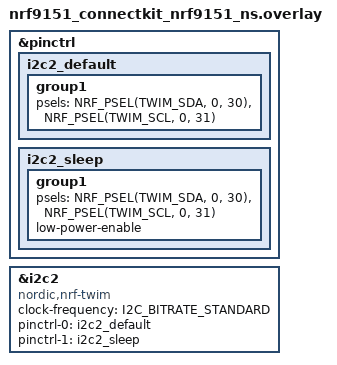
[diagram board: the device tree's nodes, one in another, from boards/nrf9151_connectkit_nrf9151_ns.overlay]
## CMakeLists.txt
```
cmake_minimum_required(VERSION 3.20.0)

find_package(Zephyr REQUIRED HINTS $ENV{ZEPHYR_BASE})
project(opencollar)

target_sources(app PRIVATE
  src/main.c
  src/app.c
  src/acks.c
  src/buzzer.c
  src/command.c
  src/config.c
  src/console.c
  src/cue.c
  src/geofence.c
  src/protocol.c
  src/provision.c
  src/rearm.c
  src/report.c
  src/shape.c
  src/slots.c
  src/store_nvs.c
  src/welfare_store.c
  third_party/monocypher/monocypher.c
  third_party/monocypher/monocypher-ed25519.c
)

target_include_directories(app PRIVATE third_party/monocypher)

# The shape rules are single precision in a fixed order of operations, to
# give the same answers as openpasture's op_geo::shape: no fused multiply-add.
target_compile_options(app PRIVATE -ffp-contract=off)
```

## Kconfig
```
mainmenu "OpenCollar"

config OPENCOLLAR_BENCH_BOUNDARY
	bool "Bench boundary from src/boundary_local.h"
	help
	  Load the boundary in src/boundary_local.h (gitignored) as version 0,
	  in RAM only, when no boundary is in force. For trying the fence and
	  cues on the bench without a server. Off on real collars, which never
	  invent a fence.

rsource "rook/Kconfig"

source "Kconfig.zephyr"
```

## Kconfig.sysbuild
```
# Partitions come from devicetree (boards/partitions_mcuboot.dtsi), not the
# Partition Manager.
config PARTITION_MANAGER
	default n

source "share/sysbuild/Kconfig"
```

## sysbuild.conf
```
# MCUboot as the first-stage bootloader; build/merged.hex = MCUboot + TF-M + app.
SB_CONFIG_BOOTLOADER_MCUBOOT=y
# DEV KEY ONLY: with no SB_CONFIG_BOOT_SIGNATURE_KEY_FILE set, images are signed
# with MCUboot's public default key (bootloader/mcuboot/root-ec-p256.pem in the
# SDK). Anyone can sign images for it. Replace with a project key kept outside
# this repo before any field build (the key is frozen into MCUboot at manufacture).
SB_CONFIG_BOOT_SIGNATURE_TYPE_ECDSA_P256=y
```

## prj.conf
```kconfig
# TF-M
CONFIG_TFM_PROFILE_TYPE_MINIMAL=y

# General
CONFIG_FPU=y
# Ed25519 checks run on the main thread, never on the system workqueue
CONFIG_MAIN_STACK_SIZE=8192
CONFIG_HEAP_MEM_POOL_SIZE=2048
CONFIG_SYSTEM_WORKQUEUE_STACK_SIZE=1536
CONFIG_POLL=y

# Logging over the USB serial port. Deferred, so printing a log line never
# holds interrupts off while a long command arrives on the same port.
CONFIG_LOG=y
CONFIG_LOG_MODE_DEFERRED=y
CONFIG_LOG_BUFFER_SIZE=4096
CONFIG_LOG_PROCESS_THREAD_STACK_SIZE=2048
CONFIG_CBPRINTF_FP_SUPPORT=y

# Console line input: provision, status and bench commands (src/console.c)
CONFIG_SERIAL=y
CONFIG_UART_INTERRUPT_DRIVEN=y

# Flash storage (NVS on the 64 KB `storage` partition): provisioning,
# config, slots and pending acks
CONFIG_FLASH=y
CONFIG_FLASH_MAP=y
CONFIG_FLASH_PAGE_LAYOUT=y
CONFIG_NVS=y
CONFIG_NVS_LOOKUP_CACHE=y
CONFIG_NVS_DATA_CRC=y
# The storage area was part of the application area before 0.2
CONFIG_NVS_INIT_BAD_MEMORY_REGION=y

# Modem and GNSS
CONFIG_NRF_MODEM_LIB=y
CONFIG_LTE_LINK_CONTROL=y

# GNSS LNA on this board is powered from the nRF9151 COEX0 pin
CONFIG_MODEM_ANTENNA=y
CONFIG_MODEM_ANTENNA_GNSS_EXTERNAL=y
CONFIG_MODEM_ANTENNA_AT_COEX0="AT%XCOEX0=1,1,1565,1586"

# Qwiic Buzzer
CONFIG_I2C=y
```

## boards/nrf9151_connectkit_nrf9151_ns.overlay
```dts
/*
 * Qwiic Buzzer on I2C2: SDA = P0.30, SCL = P0.31 (header pins 30 and 31).
 * The buzzer board has its own 2.2k pull-ups. VIO must be 3.3V (IFMCU `viosel`).
 */

/* MCUboot layout shared with the bootloader image (sysbuild/mcuboot.overlay). */
#include "partitions_mcuboot.dtsi"
#include <samples/cellular/nrf91_sram_partitions.dtsi>

&pinctrl {
	i2c2_default: i2c2_default {
		group1 {
			psels = <NRF_PSEL(TWIM_SDA, 0, 30)>,
				<NRF_PSEL(TWIM_SCL, 0, 31)>;
		};
	};

	i2c2_sleep: i2c2_sleep {
		group1 {
			psels = <NRF_PSEL(TWIM_SDA, 0, 30)>,
				<NRF_PSEL(TWIM_SCL, 0, 31)>;
			low-power-enable;
		};
	};
};

&i2c2 {
	compatible = "nordic,nrf-twim";
	status = "okay";
	clock-frequency = <I2C_BITRATE_STANDARD>;
	pinctrl-0 = <&i2c2_default>;
	pinctrl-1 = <&i2c2_sleep>;
	pinctrl-names = "default", "sleep";
};
```

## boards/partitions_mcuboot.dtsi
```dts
/*
 * Flash layout with MCUboot (NCS 3.4.1 nrf91_bootloader_partitions.dtsi
 * layout), every edge on a 32 KB SPU region boundary:
 *   0x00000-0x10000  MCUboot (64 KB)
 *   0x10000-0x80000  slot0 / primary (448 KB): TF-M 32 KB + app 416 KB
 *   0x80000-0xF0000  slot1 / secondary (448 KB), for future FOTA
 *   0xF0000-0x100000 storage (64 KB, NVS; same place as firmware 0.2)
 * Included by the app board overlay AND sysbuild/mcuboot.overlay so the
 * bootloader and the application agree on the map.
 */
#include <samples/cellular/nrf91_bootloader_partitions.dtsi>
```

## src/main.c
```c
/*
 * OpenCollar 0.2: GNSS fix -> slots and geofence -> audio cue, logged over
 * serial, with provisioning and bench commands on the same serial port.
 *
 * Boot: provisioning, config and slots come from flash (NVS); the latest
 * active boundary is enforced at once, staged ones wait for the first GNSS
 * fix. No boundary means no fence and no cues. GNSS time is the only clock
 * for boundary activation. Everything else is in app.c, which host tests
 * drive the same way. Boundary download over LTE waits for the SIM; until
 * then a signed command can be pasted on the console (`boundary <command>`).
 */
#include <zephyr/kernel.h>
#include <zephyr/logging/log.h>
#include <zephyr/sys/printk.h>
#include <modem/lte_lc.h>
#include <modem/nrf_modem_lib.h>
#include <nrf_modem_gnss.h>

#include "app.h"
#include "boundary.h"
#include "buzzer.h"
#include "console.h"
#include "store.h"

LOG_MODULE_REGISTER(opencollar, LOG_LEVEL_INF);

static const struct geofence_config geofence_defaults = {
	.warn_m = 5.0,
	.hysteresis_m = 1.0,
	.max_accuracy_m = 10.0,
};

static const struct cue_config cue_cfg = {
	.warn_freq_hz = 2730, /* Buzzer's resonant frequency: loudest */
	.outside_freq_hz = 1000,
	.beep_ms = 300,
	.max_active_ms = 20000,
	.rest_ms = 30000,
	.outside_max_ms = 10000,
	/* Welfare: PR #2 approved caps (cue.h WELFARE_DEFAULT_*). */
	.max_outside_cues = WELFARE_DEFAULT_MAX_OUTSIDE_CUES,
	.escape_cycle_limit = WELFARE_DEFAULT_ESCAPE_CYCLE_LIMIT,
	.escape_cycle_window_ms = WELFARE_DEFAULT_ESCAPE_WINDOW_MS,
};

struct fix {
	bool valid;
	bool has_time;
	double lat;
	double lon;
	float accuracy;
	uint8_t sats_tracked;
	uint8_t sats_in_fix;
	int64_t utc;
};

K_MSGQ_DEFINE(fix_q, sizeof(struct fix), 4, 8);
static struct k_poll_signal console_sig = K_POLL_SIGNAL_INITIALIZER(console_sig);

/* Everything the collar knows, in static RAM (see BUILD-LOG for the budget) */
static struct app app;
static char reply[256];
static uint32_t store_errors_seen;

static void gnss_event_handler(int event)
{
	struct nrf_modem_gnss_pvt_data_frame pvt;
	struct fix f = {0};

	if (event != NRF_MODEM_GNSS_EVT_PVT) {
		return;
	}
	if (nrf_modem_gnss_read(&pvt, sizeof(pvt), NRF_MODEM_GNSS_DATA_PVT) != 0) {
		return;
	}

	for (int i = 0; i < NRF_MODEM_GNSS_MAX_SATELLITES; i++) {
		if (pvt.sv[i].sv == 0) {
			continue;
		}
		f.sats_tracked++;
		if (pvt.sv[i].flags & NRF_MODEM_GNSS_SV_FLAG_USED_IN_FIX) {
			f.sats_in_fix++;
		}
	}

	f.valid = pvt.flags & NRF_MODEM_GNSS_PVT_FLAG_FIX_VALID;
	f.lat = pvt.latitude;
	f.lon = pvt.longitude;
	f.accuracy = pvt.accuracy;
	if (f.valid) {
		/* The fix's own UTC: the clock for boundary activation */
		f.has_time = true;
		f.utc = proto_time_civil(pvt.datetime.year, pvt.datetime.month, pvt.datetime.day,
					 pvt.datetime.hour, pvt.datetime.minute,
					 pvt.datetime.seconds);
	}

	/* Drop the fix if the main loop is behind; the next one is a second away */
	k_msgq_put(&fix_q, &f, K_NO_WAIT);
}

static int gnss_start(void)
{
	int err;

	err = nrf_modem_lib_init();
	if (err) {
		LOG_ERR("Modem library init failed: %d", err);
		return err;
	}

	err = lte_lc_system_mode_set(LTE_LC_SYSTEM_MODE_LTEM_GPS, LTE_LC_SYSTEM_MODE_PREFER_AUTO);
	if (err) {
		LOG_ERR("System mode set failed: %d", err);
		return err;
	}

	/* GNSS only until the SIM is in: LTE isn't needed for local fencing */
	err = lte_lc_func_mode_set(LTE_LC_FUNC_MODE_ACTIVATE_GNSS);
	if (err) {
		LOG_ERR("Failed to activate GNSS: %d", err);
		return err;
	}

	err = nrf_modem_gnss_event_handler_set(gnss_event_handler);
	if (!err) {
		err = nrf_modem_gnss_fix_interval_set(1);
	}
	if (!err) {
		err = nrf_modem_gnss_start();
	}
	if (err) {
		LOG_ERR("GNSS start failed: %d", err);
	}
	return err;
}

static void log_ack(const struct slot_ack *ack)
{
	char at[24] = "-";

	if (ack->has_at) {
		proto_time_format(ack->at, at, sizeof(at));
	}
	LOG_INF("ack v%u %s%s%s at %s (%u pending)", ack->version, ack_status_str(ack->status),
		ack->code ? " " : "", reject_str(ack->code), at, app.acks.n);
}

static void check_store(void)
{
	uint32_t errors = app.slots.store_errors + app.cfg.store_errors;

	if (errors != store_errors_seen) {
		LOG_WRN("Flash writes failed: %u so far", errors);
		store_errors_seen = errors;
	}
}

static void handle_fix(const struct fix *f)
{
	static int64_t last_no_fix_log;
	int64_t now = k_uptime_get();
	struct app_fix_in in = {
		.valid = f->valid,
		.lat = f->lat,
		.lon = f->lon,
		.accuracy_m = f->accuracy,
		.has_time = f->has_time,
		.utc = f->utc,
	};
	struct app_fix_out out = app_fix(&app, &in, now);
	struct episode ep;
	struct welfare_event we;

	if (out.applied) {
		LOG_INF("event: staged boundary v%u now in force", out.ack.version);
		log_ack(&out.ack);
		check_store();
	}

	if (!f->valid) {
		if (now - last_no_fix_log >= 10000) {
			last_no_fix_log = now;
			LOG_INF("searching: %u tracked, %u in fix", f->sats_tracked, f->sats_in_fix);
		}
		return;
	}

	/* GNSS UTC on every fix line, so a host reading the log never stamps its own time */
	char at[24] = "-";

	if (f->has_time) {
		proto_time_format(f->utc, at, sizeof(at));
	}

	if (!out.fenced) {
		LOG_INF("fix %.6f,%.6f acc=%.1fm sats=%u (no boundary) at=%s", f->lat, f->lon,
			(double)f->accuracy, f->sats_in_fix, at);
		return;
	}

	if (out.cmd.active) {
		buzzer_play(out.cmd.freq_hz, out.cmd.volume, out.cmd.duration_ms);
	}

	LOG_INF("fix %.6f,%.6f acc=%.1fm sats=%u v%u state=%s margin=%.1fm ring=%d%s%s cue=%s vol=%u "
		"at=%s",
		f->lat, f->lon, (double)f->accuracy, f->sats_in_fix, out.version,
		geofence_state_str(out.r.state), out.r.margin_m, out.r.nearest_ring,
		out.r.degraded ? " (degraded)" : "",
		app.cue.mode == CUE_MODE_TRACK
			? " (track)"
			: (app.cue.enforcement_off ? " (enforcement off)"
						   : (app.cue.armed ? "" : " (unarmed)")),
		out.cmd.active ? cue_kind_str(out.cmd.kind) : "off", out.cmd.volume, at);

	if (out.r.changed) {
		LOG_INF("event: state -> %s", geofence_state_str(out.r.state));
	}
	while (cue_take_episode(&app.cue, &ep)) {
		LOG_INF("episode: %s ring=%d cues=%u max=%u min_margin=%.1fm %lld ms",
			episode_outcome_str(ep.outcome), ep.ring, ep.cues, ep.max_level,
			ep.min_margin_m, ep.end - ep.start);
	}
	while (cue_take_welfare(&app.cue, &we)) {
		LOG_INF("welfare: %s outside_cues=%u escape_cycles=%u at=%lld",
			welfare_event_str(we.kind), we.outside_cues, we.escape_cycles,
			(long long)we.at_ms);
	}
}

static void handle_line(void)
{
	size_t len;
	bool overflow;
	const char *line = console_line(&len, &overflow);
	uint32_t acks_before = app.acks.n;
	uint32_t version_before = app.fence ? app.fence->version : 0;
	bool fenced_before = app.fence != NULL;

	if (!line) {
		return;
	}
	app_line(&app, line, len, overflow, k_uptime_get(), reply, sizeof(reply));
	console_release();
	if (reply[0]) {
		printk("%s\n", reply);
	}
	if (app.acks.n != acks_before && app.acks.n > 0) {
		log_ack(&app.acks.q[app.acks.n - 1]);
	}
	if (app.fence && (!fenced_before || app.fence->version != version_before)) {
		LOG_INF("event: boundary v%u in force: %d rings, %d vertices", app.fence->version,
			app.fence->rings, app.fence->n);
	} else if (!app.fence && fenced_before) {
		LOG_INF("event: no boundary: no cues");
	}
	check_store();
}

static void log_boot_state(void)
{
	const struct slot_hdr *act = slots_active(&app.slots);
	uint32_t staged = app.slots.n - (act ? 1 : 0);

	if (!app.prov.ok) {
		LOG_INF("Not provisioned: GNSS only. Paste the card: provision {...}");
		return;
	}
	LOG_INF("Collar %s, herd %s, config %s", app.prov.collar_id.s, app_herd(&app)->s,
		app.cfg.has ? "stored" : "none");
	if (act && app.fence) {
		LOG_INF("Boundary v%u enforced from flash: %d rings, %d vertices%s", act->version,
			app.fence->rings, app.fence->n,
			(act->flags & SLOT_F_TRACK) ? ", track mode" : "");
	} else {
		LOG_INF("No boundary: no cues");
	}
	if (staged) {
		LOG_INF("%u staged boundaries wait for the first GNSS fix", staged);
	}
	if (app.acks.n) {
		LOG_INF("%u acks pending", app.acks.n);
	}
}

int main(void)
{
	struct fix f;
	int err;
	struct k_poll_event events[] = {
		K_POLL_EVENT_STATIC_INITIALIZER(K_POLL_TYPE_MSGQ_DATA_AVAILABLE,
						K_POLL_MODE_NOTIFY_ONLY, &fix_q, 0),
		K_POLL_EVENT_STATIC_INITIALIZER(K_POLL_TYPE_SIGNAL, K_POLL_MODE_NOTIFY_ONLY,
						&console_sig, 0),
	};

	LOG_INF("OpenCollar %s starting", APP_FW_VERSION);

	err = store_init();
	if (err) {
		LOG_ERR("Flash storage unavailable (%d): nothing will be kept over a reboot", err);
	}

	app_init(&app, &cue_cfg, &geofence_defaults);
	app_boot(&app, k_uptime_get());
	log_boot_state();

#ifdef CONFIG_OPENCOLLAR_BENCH_BOUNDARY
	if (app_bench(&app, boundary_vertices, ARRAY_SIZE(boundary_vertices), k_uptime_get())) {
		LOG_INF("Bench boundary loaded as v0: %u vertices",
			(unsigned)ARRAY_SIZE(boundary_vertices));
	}
#endif

	err = console_init(&console_sig);
	if (err) {
		LOG_ERR("Console input unavailable: %d", err);
	}

	if (buzzer_init() == 0) {
		/* Short chirp so you know the cue path works at boot (not a cue) */
		buzzer_play(cue_cfg.warn_freq_hz, 2, 150);
	}

	if (gnss_start() == 0) {
		LOG_INF("GNSS started");
	}

	while (true) {
		k_poll(events, ARRAY_SIZE(events), K_FOREVER);

		if (events[0].state == K_POLL_STATE_MSGQ_DATA_AVAILABLE) {
			while (k_msgq_get(&fix_q, &f, K_NO_WAIT) == 0) {
				handle_fix(&f);
			}
		}
		if (events[1].state == K_POLL_STATE_SIGNALED) {
			k_poll_signal_reset(&console_sig);
			handle_line();
		}
		events[0].state = K_POLL_STATE_NOT_READY;
		events[1].state = K_POLL_STATE_NOT_READY;
	}

	return 0;
}
```

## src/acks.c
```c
#include "acks.h"

#include <string.h>

#include "store.h"

#define ACKS_MAGIC 0x314b434fu /* "OCK1" */
/* version, status, code, has_at, id length, at (8), id (64) */
#define ACK_BYTES (4 + 4 + 8 + PROTO_MAX_ID_BYTES)
#define ACKS_BYTES (8 + ACKS_MAX * ACK_BYTES + 4)

static uint8_t buf[ACKS_BYTES];

static void put32(uint8_t *p, uint32_t v)
{
	for (int k = 0; k < 4; k++) {
		p[k] = (uint8_t)(v >> (8 * k));
	}
}

static uint32_t get32(const uint8_t *p)
{
	return (uint32_t)p[0] | (uint32_t)p[1] << 8 | (uint32_t)p[2] << 16 | (uint32_t)p[3] << 24;
}

static int save(const struct acks *a)
{
	uint8_t *p = buf + 8;
	size_t len;

	if (a->n == 0) {
		return store_delete(STORE_ID_ACKS);
	}
	put32(buf, ACKS_MAGIC);
	buf[4] = a->n;
	buf[5] = buf[6] = buf[7] = 0;
	for (int i = 0; i < a->n; i++) {
		const struct slot_ack *k = &a->q[i];

		memset(p, 0, ACK_BYTES);
		put32(p, k->version);
		p[4] = k->status;
		p[5] = k->code;
		p[6] = k->has_at;
		p[7] = k->command_id.len;
		put32(p + 8, (uint32_t)k->at);
		put32(p + 12, (uint32_t)((uint64_t)k->at >> 32));
		memcpy(p + 16, k->command_id.s, k->command_id.len);
		p += ACK_BYTES;
	}
	len = (size_t)(p - buf);
	put32(p, proto_crc32(0, buf, len));
	return store_write(STORE_ID_ACKS, buf, len + 4);
}

void acks_load(struct acks *a)
{
	int len = store_read(STORE_ID_ACKS, buf, sizeof(buf));

	memset(a, 0, sizeof(*a));
	if (len < 12 || len > (int)sizeof(buf) || get32(buf) != ACKS_MAGIC || buf[4] > ACKS_MAX ||
	    len != 8 + buf[4] * ACK_BYTES + 4 ||
	    get32(buf + len - 4) != proto_crc32(0, buf, (size_t)len - 4)) {
		return;
	}
	for (int i = 0; i < buf[4]; i++) {
		const uint8_t *p = buf + 8 + i * ACK_BYTES;
		struct slot_ack *k = &a->q[a->n];

		if (!proto_id_set(&k->command_id, (const char *)p + 16, p[7])) {
			continue;
		}
		k->version = get32(p);
		k->status = p[4];
		k->code = p[5];
		k->has_at = p[6] != 0;
		k->at = (int64_t)((uint64_t)get32(p + 8) | (uint64_t)get32(p + 12) << 32);
		a->n++;
	}
}

int acks_push(struct acks *a, const struct slot_ack *ack)
{
	if (a->n == ACKS_MAX) {
		memmove(&a->q[0], &a->q[1], (ACKS_MAX - 1) * sizeof(a->q[0]));
		a->n--;
	}
	a->q[a->n++] = *ack;
	return save(a);
}

const struct slot_ack *acks_peek(const struct acks *a)
{
	return a->n > 0 ? &a->q[0] : NULL;
}

int acks_pop(struct acks *a)
{
	if (a->n == 0) {
		return 0;
	}
	memmove(&a->q[0], &a->q[1], (size_t)(a->n - 1) * sizeof(a->q[0]));
	a->n--;
	return save(a);
}

int acks_clear(struct acks *a)
{
	a->n = 0;
	return store_delete(STORE_ID_ACKS);
}
```

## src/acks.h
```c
/*
 * Acks waiting to be delivered (protocol v1 §3.3). They survive a reboot in
 * NVS id 2 until the server takes them. Plain C over store.h, host-testable.
 *
 * The queue holds the newest ACKS_MAX; when it is full the oldest goes (the
 * next report's `slots` list is the ground truth for what the collar holds).
 */
#ifndef OPENCOLLAR_ACKS_H
#define OPENCOLLAR_ACKS_H

#include <stdbool.h>
#include <stdint.h>

#include "slots.h"

#define ACKS_MAX 16

struct acks {
	struct slot_ack q[ACKS_MAX];
	uint8_t n;
};

/* Load from the store (an unreadable entry reads as empty) */
void acks_load(struct acks *a);
/* Queue one and persist. Returns 0 or a negative errno from the store. */
int acks_push(struct acks *a, const struct slot_ack *ack);
/* The oldest, if any */
const struct slot_ack *acks_peek(const struct acks *a);
/* The oldest was delivered */
int acks_pop(struct acks *a);
/* Provisioning: forget them all */
int acks_clear(struct acks *a);

#endif
```

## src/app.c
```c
#include "app.h"

#include <stdio.h>
#include <string.h>

static void apply_boundary(void *ctx, const struct slot_hdr *hdr, const int32_t (*v)[2])
{
	struct app *a = ctx;
	struct geofence *next = a->fence == &a->fences[0] ? &a->fences[1] : &a->fences[0];
	struct geofence_config cfg = a->defaults;

	cfg.warn_m = hdr->warn_m;
	cfg.hysteresis_m = hdr->hysteresis_m;

	/* Build into the scratch fence, then swap: the old one stays in force
	 * until the new one is complete */
	if (geofence_init_e7(next, &cfg, v, hdr->ring_len, hdr->rings, hdr->version) != 0) {
		return;
	}
	a->fence = next;
	cue_rearm_at(&a->cue, a->now_ms);
	cue_set_mode(&a->cue, (hdr->flags & SLOT_F_TRACK) ? CUE_MODE_TRACK : CUE_MODE_AUDIO);
}

void app_init(struct app *a, const struct cue_config *cue_cfg,
	      const struct geofence_config *defaults)
{
	memset(a, 0, sizeof(*a));
	a->defaults = *defaults;
	cue_init(&a->cue, cue_cfg);
	config_init(&a->cfg);
	slots_init(&a->slots, &LIMITS_V0, a->e7, apply_boundary, a);
	a->slots.warn_m = defaults->warn_m;
	a->slots.hysteresis_m = defaults->hysteresis_m;
}

const struct proto_id *app_herd(const struct app *a)
{
	if (!a->prov.ok) {
		return NULL;
	}
	return a->cfg.has_herd ? &a->cfg.herd : &a->prov.herd_id;
}

static void set_ids(struct app *a)
{
	slots_set_herd(&a->slots, app_herd(a));
	slots_set_collar(&a->slots, a->prov.ok ? &a->prov.collar_id : NULL);
}

void app_boot(struct app *a, int64_t now_ms)
{
	a->now_ms = now_ms;
	a->has_clock = false;
	a->fence = NULL;
	cue_rearm_at(&a->cue, now_ms);

	provision_load(&a->prov);
	if (!a->prov.ok) {
		return; /* GNSS only */
	}
	config_load(&a->cfg);
	set_ids(a);
	slots_load(&a->slots);
	acks_load(&a->acks);
}

bool app_bench(struct app *a, const struct geo_point *vertices, int n, int64_t now_ms)
{
	struct geofence *next = a->fence == &a->fences[0] ? &a->fences[1] : &a->fences[0];

	if (a->fence) {
		return false;
	}
	if (geofence_init(next, &a->defaults, vertices, n, 0) != 0) {
		return false;
	}
	a->fence = next;
	cue_rearm_at(&a->cue, now_ms);
	cue_set_mode(&a->cue, CUE_MODE_AUDIO);
	return true;
}

bool app_now(const struct app *a, int64_t now_ms, int64_t *utc)
{
	if (!a->has_clock) {
		return false;
	}
	*utc = a->clock_utc + (now_ms - a->clock_ms) / 1000;
	return true;
}

struct app_fix_out app_fix(struct app *a, const struct app_fix_in *f, int64_t now_ms)
{
	struct app_fix_out out = {0};

	a->now_ms = now_ms;
	if (f->valid && f->has_time) {
		a->has_clock = true;
		a->clock_utc = f->utc;
		a->clock_ms = now_ms;
		if (a->prov.ok && slots_tick(&a->slots, f->utc, &out.ack)) {
			out.applied = true;
			acks_push(&a->acks, &out.ack);
		}
	}
	if (a->fence) {
		out.fenced = true;
		out.version = a->fence->version;
	}
	if (!f->valid || !a->fence) {
		return out;
	}

	struct geo_point p = {.lat = f->lat, .lon = f->lon};

	out.r = geofence_update(a->fence, p, f->accuracy_m);
	out.cmd = cue_update(&a->cue, &out.r, a->fence->cfg.warn_m, now_ms);
	return out;
}

/* Best effort for an ack when a command fails before its fields can be read */
static bool unverified_ack(const char *wire, size_t len, enum reject_code code,
			   struct slot_ack *ack)
{
	struct wire_scan sc;
	const struct wire_span *id, *ver;

	memset(ack, 0, sizeof(*ack));
	if (wire_scan(wire, len, &sc) != REJECT_NONE) {
		return false;
	}
	id = wire_find(wire, &sc, "command_id");
	ver = wire_find(wire, &sc, "version");
	if (!id || !ver || !wire_read_id(wire, id, false, NULL, &ack->command_id) ||
	    !wire_u32(wire + ver->val, ver->val_len, &ack->version)) {
		return false;
	}
	ack->status = ACK_REJECTED;
	ack->code = (uint8_t)code;
	return true;
}

enum reject_code app_boundary(struct app *a, const char *wire, size_t len, int64_t now_ms,
			      struct slot_ack *ack, bool *has_ack)
{
	enum reject_code code;
	int64_t now = 0;
	bool has_now;

	*has_ack = false;
	a->now_ms = now_ms;
	if (!a->prov.ok) {
		return REJECT_BAD_SIG; /* No server key to check it with */
	}

	has_now = app_now(a, now_ms, &now);
	code = command_parse(wire, len, a->prov.server_key, &a->cmd, a->e7, SHAPE_BUF_VERTICES);
	if (code != REJECT_NONE) {
		if (unverified_ack(wire, len, code, ack)) {
			ack->has_at = has_now;
			ack->at = has_now ? now : 0;
			acks_push(&a->acks, ack);
			*has_ack = true;
		}
		return code;
	}

	*ack = slots_insert(&a->slots, &a->cmd, has_now, now);
	acks_push(&a->acks, ack);
	*has_ack = true;
	return (enum reject_code)ack->code;
}

enum reject_code app_config(struct app *a, const char *wire, size_t len, int64_t now_ms)
{
	int64_t now = 0;
	bool has_now;
	enum reject_code code;

	a->now_ms = now_ms;
	if (!a->prov.ok) {
		return REJECT_BAD_SIG;
	}
	has_now = app_now(a, now_ms, &now);
	code = config_receive(&a->cfg, wire, len, a->prov.server_key, &a->prov.collar_id,
			      a->prov.endpoint, has_now, now);
	if (code == REJECT_NONE) {
		/* A new herd drops the old herd's staged slots. The config is stored
		 * first; a power cut before the deletes is tidied up at boot. */
		set_ids(a);
	}
	return code;
}

static void do_provision(struct app *a, const char *payload, size_t len, char *reply,
			 size_t cap)
{
	struct provision p;
	enum prov_error e = provision_parse(payload, len, &p);

	if (e != PROV_OK) {
		snprintf(reply, cap, "error %s", prov_error_str(e));
		return;
	}

	/* Wipe first: a power cut part way leaves the old provisioning with
	 * fewer slots, never the new provisioning with the old server's slots */
	slots_wipe(&a->slots);
	config_wipe(&a->cfg);
	acks_clear(&a->acks);
	a->fence = NULL;
	cue_rearm_at(&a->cue, a->now_ms);
	cue_set_mode(&a->cue, CUE_MODE_AUDIO);

	if (provision_save(payload, len) != 0) {
		snprintf(reply, cap, "error %s", prov_error_str(PROV_STORE_FAILED));
		set_ids(a);
		return;
	}
	a->prov = p;
	set_ids(a);
	snprintf(reply, cap, "ok %s", a->prov.collar_id.s);
}

static void do_status(struct app *a, char *reply, size_t cap)
{
	size_t n;
	const struct slot_hdr *act = slots_active(&a->slots);

	if (!a->prov.ok) {
		snprintf(reply, cap, "unprovisioned fw %s", APP_FW_VERSION);
		return;
	}

	const struct proto_id *herd = app_herd(a);

	n = (size_t)snprintf(reply, cap, "collar %s herd %s fw %s config ", a->prov.collar_id.s,
			     herd->s, APP_FW_VERSION);
	if (n < cap) {
		n += (size_t)(a->cfg.has ? snprintf(reply + n, cap - n, "%u", (unsigned)a->cfg.version)
					 : snprintf(reply + n, cap - n, "-"));
	}
	if (n < cap) {
		n += (size_t)(act ? snprintf(reply + n, cap - n, " active %u slots",
					     (unsigned)act->version)
				  : snprintf(reply + n, cap - n, " active - slots"));
	}
	for (int i = 0; i < a->slots.n && n < cap; i++) {
		n += (size_t)snprintf(reply + n, cap - n, " %u", (unsigned)a->slots.s[i].version);
	}
	if (a->slots.n == 0 && n < cap) {
		n += (size_t)snprintf(reply + n, cap - n, " -");
	}
	if (n < cap) {
		snprintf(reply + n, cap - n, " enforcement %s",
			 a->cue.enforcement_off ? "off" : "on");
	}
}

static void do_boundary(struct app *a, const char *wire, size_t len, bool overflow, char *reply,
			size_t cap)
{
	struct slot_ack ack;
	bool has_ack;
	enum reject_code code;

	if (!a->prov.ok) {
		snprintf(reply, cap, "error unprovisioned");
		return;
	}
	if (overflow) {
		snprintf(reply, cap, "error %s", reject_str(REJECT_TOO_LARGE));
		return;
	}
	code = app_boundary(a, wire, len, a->now_ms, &ack, &has_ack);
	if (!has_ack) {
		snprintf(reply, cap, "error %s", reject_str(code));
	} else if (ack.status == ACK_REJECTED) {
		snprintf(reply, cap, "rejected %u %s", (unsigned)ack.version, reject_str(ack.code));
	} else {
		snprintf(reply, cap, "%s %u", ack_status_str(ack.status), (unsigned)ack.version);
	}
}

static void do_config(struct app *a, const char *wire, size_t len, char *reply, size_t cap)
{
	enum reject_code code;

	if (!a->prov.ok) {
		snprintf(reply, cap, "error unprovisioned");
		return;
	}
	code = app_config(a, wire, len, a->now_ms);
	if (code != REJECT_NONE) {
		snprintf(reply, cap, "error %s", reject_str(code));
	} else {
		snprintf(reply, cap, "ok %u", (unsigned)a->cfg.version);
	}
}

/* `word` then a space (or the end of the line); *rest is what follows */
static bool command_is(const char *line, size_t len, const char *word, const char **rest,
		       size_t *rest_len)
{
	size_t n = strlen(word);

	if (len < n || memcmp(line, word, n) != 0 || (len > n && line[n] != ' ')) {
		return false;
	}
	*rest = line + n;
	*rest_len = len - n;
	while (*rest_len > 0 && **rest == ' ') {
		(*rest)++;
		(*rest_len)--;
	}
	return true;
}

void app_line(struct app *a, const char *line, size_t len, bool overflow, int64_t now_ms,
	      char *reply, size_t cap)
{
	const char *rest;
	size_t rest_len;

	a->now_ms = now_ms;
	reply[0] = '\0';

	/* Trim spaces around the line (terminals and scanners add them) */
	while (len > 0 && (line[0] == ' ' || line[0] == '\t')) {
		line++;
		len--;
	}
	while (len > 0 && (line[len - 1] == ' ' || line[len - 1] == '\t')) {
		len--;
	}
	if (len == 0) {
		return;
	}

	if (command_is(line, len, "boundary", &rest, &rest_len)) {
		do_boundary(a, rest, rest_len, overflow, reply, cap);
	} else if (overflow) {
		snprintf(reply, cap, "error too_long");
	} else if (command_is(line, len, "provision", &rest, &rest_len)) {
		do_provision(a, rest, rest_len, reply, cap);
	} else if (command_is(line, len, "status", &rest, &rest_len) && rest_len == 0) {
		do_status(a, reply, cap);
	} else if (command_is(line, len, "rearm", &rest, &rest_len) && rest_len == 0) {
		/* Explicit caretaker clear of auto shut-off (not a fence move). */
		cue_clear_shutoff_at(&a->cue, now_ms);
		snprintf(reply, cap, "ok enforcement %s",
			 a->cue.enforcement_off ? "off" : "on");
	} else if (command_is(line, len, "config", &rest, &rest_len)) {
		do_config(a, rest, rest_len, reply, cap);
	} else {
		snprintf(reply, cap, "error unknown_command");
	}
}
```

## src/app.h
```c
/*
 * The collar's core, without Zephyr: provisioning, config, slots, pending
 * acks, welfare/rearm persistence, the fence and the cue policy, wired
 * together. main.c feeds it GNSS fixes and console lines and plays what it
 * returns; host tests drive it the same way.
 *
 * Clocks: now_ms is uptime (monotonic, for cue timing). GNSS UTC from fixes
 * is the only clock for boundary activation, ack times and rearm expiry;
 * between fixes it is carried forward on the uptime counter. Nothing unsigned
 * from a server sets it.
 *
 * Boot: provisioning from NVS id 1 (none: GNSS only), config from id 3,
 * welfare/rearm from id 5 (shut-off restored so a reboot does not resume
 * enforcement; rearm_seq never lowered), slots from 0x100 + i with the latest
 * active boundary enforced at once, pending acks from id 2. No stored
 * boundary means no fence and no cues; the collar never invents one (a bench
 * boundary only with CONFIG_OPENCOLLAR_BENCH_BOUNDARY, as version 0, RAM only).
 *
 * Console lines (§3.9):
 *   provision <payload>  -> ok <collar id> | error <code>
 *   status               -> collar id, herd id, fw, config version, slots
 *   boundary <command>   -> the same path as a download: applied/received/rejected
 *   config <command>     -> the same path as a report response: ok <version> | error <code>
 *   rearm                -> caretaker clear of shut-off (persisted; by:serial)
 *   rearm <command>      -> signed server rearm (same path as a report response)
 */
#ifndef OPENCOLLAR_APP_H
#define OPENCOLLAR_APP_H

#include <stdbool.h>
#include <stddef.h>
#include <stdint.h>

#include "acks.h"
#include "command.h"
#include "config.h"
#include "cue.h"
#include "geofence.h"
#include "provision.h"
#include "rearm.h"
#include "slots.h"
#include "welfare_store.h"

#define APP_FW_VERSION "0.2.0"

struct app_fix_in {
	bool valid;
	double lat, lon;
	double accuracy_m;
	bool has_time;
	int64_t utc; /* GNSS UTC of this fix, Unix seconds */
};

struct app_fix_out {
	bool fenced; /* A boundary is in force */
	uint32_t version;
	struct geofence_result r;
	struct cue_command cmd;
	bool applied; /* A staged boundary took effect at this fix */
	struct slot_ack ack;
};

struct app {
	struct provision prov;
	struct config cfg;
	struct slots slots;
	struct acks acks;
	struct welfare_store welfare;
	struct geofence_config defaults;
	struct geofence fences[2]; /* The active one and a scratch one to build into */
	struct geofence *fence;    /* NULL: no boundary, no cues */
	struct cue cue;
	bool has_clock;
	int64_t clock_utc;
	int64_t clock_ms;
	int64_t now_ms; /* Uptime of the call in progress */
	int32_t e7[SHAPE_BUF_VERTICES][2];
	struct boundary_cmd cmd;
	struct rearm_cmd rearm_cmd;
};

void app_init(struct app *a, const struct cue_config *cue_cfg,
	      const struct geofence_config *defaults);

/* Load everything from the store and enforce the active boundary */
void app_boot(struct app *a, int64_t now_ms);

/* A bench boundary as version 0 (RAM only), when no boundary is in force */
bool app_bench(struct app *a, const struct geo_point *vertices, int n, int64_t now_ms);

struct app_fix_out app_fix(struct app *a, const struct app_fix_in *fix, int64_t now_ms);

/* A downloaded boundary command. The ack (if any) is queued and copied to *ack. */
enum reject_code app_boundary(struct app *a, const char *wire, size_t len, int64_t now_ms,
			      struct slot_ack *ack, bool *has_ack);

/* A config command from a report response */
enum reject_code app_config(struct app *a, const char *wire, size_t len, int64_t now_ms);

/*
 * A signed rearm command (report response or serial). On success clears
 * shut-off, persists rearm_seq, acks applied with version=rearm_seq.
 */
enum reject_code app_rearm(struct app *a, const char *wire, size_t len, int64_t now_ms,
			   struct slot_ack *ack, bool *has_ack);

/* One console line (without the line ending). The reply is NUL-terminated;
 * empty when there is nothing to say. */
void app_line(struct app *a, const char *line, size_t len, bool overflow, int64_t now_ms,
	      char *reply, size_t cap);

/* GNSS time now, carried forward from the last fix; false before the first */
bool app_now(const struct app *a, int64_t now_ms, int64_t *utc);

/* The herd boundaries are checked against: the config's, else provisioning's */
const struct proto_id *app_herd(const struct app *a);

#endif
```

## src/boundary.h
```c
/*
 * Bench boundary, for trying the fence and cues without a server.
 *
 * Only with CONFIG_OPENCOLLAR_BENCH_BOUNDARY=y (default n). Put the boundary
 * in boundary_local.h (gitignored, so farm and home locations stay out of the
 * public repo):
 *
 *   static const struct geo_point boundary_vertices[] = {
 *           {36.16270, -86.78160}, // {lat, lon}
 *           ...
 *   };
 *
 * It is loaded as version 0, in RAM only, when no boundary is in force, so
 * any boundary from the server (version 1 and up) replaces it. A collar
 * built without this option never invents a fence.
 */
#ifndef OPENCOLLAR_BOUNDARY_H
#define OPENCOLLAR_BOUNDARY_H

#ifdef CONFIG_OPENCOLLAR_BENCH_BOUNDARY

#include "geofence.h"

#if __has_include("boundary_local.h")
#include "boundary_local.h"
#else
#error "CONFIG_OPENCOLLAR_BENCH_BOUNDARY needs src/boundary_local.h (see boundary.h)"
#endif

#endif

#endif
```

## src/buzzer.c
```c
/*
 * Register map from SparkFun's MIT-licensed Qwiic Buzzer Arduino library.
 * Multi-byte values are big-endian.
 */
#include "buzzer.h"

#include <zephyr/device.h>
#include <zephyr/drivers/i2c.h>
#include <zephyr/logging/log.h>

LOG_MODULE_REGISTER(buzzer, LOG_LEVEL_INF);

#define BUZZER_ADDR 0x34
#define BUZZER_ID   0x5E

#define REG_ID        0x00
#define REG_FREQ_MSB  0x03 /* followed by FREQ_LSB, VOLUME, DURATION_MSB, DURATION_LSB */
#define REG_ACTIVE    0x08

static const struct device *const i2c = DEVICE_DT_GET(DT_NODELABEL(i2c2));
static bool present;

int buzzer_init(void)
{
	uint8_t id = 0;
	int err;

	if (!device_is_ready(i2c)) {
		LOG_ERR("I2C bus not ready");
		return -ENODEV;
	}

	err = i2c_reg_read_byte(i2c, BUZZER_ADDR, REG_ID, &id);
	if (err) {
		LOG_WRN("Buzzer not found at 0x%02x (%d)", BUZZER_ADDR, err);
		return err;
	}
	if (id != BUZZER_ID) {
		LOG_WRN("Unexpected buzzer ID 0x%02x", id);
		return -EIO;
	}

	present = true;
	LOG_INF("Buzzer ready");
	return 0;
}

int buzzer_play(uint16_t freq_hz, uint8_t volume, uint16_t duration_ms)
{
	if (!present) {
		return -ENODEV;
	}

	uint8_t settings[] = {
		REG_FREQ_MSB,
		freq_hz >> 8, freq_hz & 0xff,
		volume > 4 ? 4 : volume,
		duration_ms >> 8, duration_ms & 0xff,
	};
	int err = i2c_write(i2c, settings, sizeof(settings), BUZZER_ADDR);

	if (err) {
		return err;
	}

	return i2c_reg_write_byte(i2c, BUZZER_ADDR, REG_ACTIVE, 1);
}

int buzzer_stop(void)
{
	if (!present) {
		return -ENODEV;
	}

	return i2c_reg_write_byte(i2c, BUZZER_ADDR, REG_ACTIVE, 0);
}
```

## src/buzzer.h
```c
/* SparkFun Qwiic Buzzer (BOB-24474) over I2C. */
#ifndef OPENCOLLAR_BUZZER_H
#define OPENCOLLAR_BUZZER_H

#include <stdint.h>

/* Returns 0 if the buzzer answered with the expected ID. */
int buzzer_init(void);

/* volume 0-4; duration_ms 0 means play until buzzer_stop(). */
int buzzer_play(uint16_t freq_hz, uint8_t volume, uint16_t duration_ms);

int buzzer_stop(void);

#endif
```

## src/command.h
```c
/*
 * Signed commands as the collar receives them (protocol v1 §3.2, §3.4).
 * Plain C, host-testable.
 *
 * The collar doesn't build a JSON tree. It scans the raw text once, records
 * up to 16 top-level key/value spans, sorts them by key bytes and streams the
 * canonical form (keys sorted, `sig` left out, value tokens copied verbatim
 * with whitespace outside strings removed) into SHA-512 to check the Ed25519
 * signature (Monocypher). Only then are the fields read, straight from the
 * spans: coordinates are converted to e7 integers exactly, with no float
 * round trip.
 *
 * Checked in this order, as openpasture's op_protocol::verify_wire:
 *  1. too_large  more than 12 288 bytes
 *  2. bad_json   not UTF-8; not one JSON object; a nested object anywhere;
 *                arrays deeper than 4; a key with a backslash; a duplicate
 *                key; more than 16 keys; anything after the object
 *  3. bad_sig    no `sig`, `sig` not a plain base64 string of 64 bytes, or a
 *                signature that doesn't verify
 *  4. bad_json   the fields don't make a command (types, required fields,
 *                ids empty or over 64 bytes). Unknown keys are signed and ignored.
 *
 * Ed25519 runs on the caller's stack: call this from the main thread (8 KB
 * stack), never from the system workqueue.
 */
#ifndef OPENCOLLAR_COMMAND_H
#define OPENCOLLAR_COMMAND_H

#include <stdbool.h>
#include <stddef.h>
#include <stdint.h>

#include "protocol.h"
#include "shape.h"

/* ---- The top-level span scanner, shared with config and provisioning ---- */

struct wire_span {
	uint16_t key, key_len; /* The key's bytes, without quotes */
	uint16_t val, val_len; /* The value token as sent */
};

struct wire_scan {
	struct wire_span span[PROTO_MAX_KEYS];
	uint8_t n;
	int8_t sig; /* Index of the `sig` span, or -1 */
};

/* Size, UTF-8 and the span scan: REJECT_NONE, REJECT_TOO_LARGE or REJECT_BAD_JSON */
enum reject_code wire_scan(const char *w, size_t len, struct wire_scan *out);

/* The canonical bytes, in pieces */
typedef void (*wire_sink)(void *ctx, const uint8_t *p, size_t n);
void wire_canonical(const char *w, const struct wire_scan *sc, wire_sink sink, void *ctx);

/* wire_scan, then the Ed25519 signature over the canonical bytes */
enum reject_code wire_verify(const char *w, size_t len, const uint8_t public_key[32],
			     struct wire_scan *out);

/* The span for a key, or NULL */
const struct wire_span *wire_find(const char *w, const struct wire_scan *sc, const char *key);

/* ---- Value tokens ---- */

bool wire_is_null(const char *t, size_t n);
/* A JSON string: decoded into out (up to cap bytes, not NUL-terminated);
 * *len is the full decoded length even when it is over cap. */
bool wire_string(const char *t, size_t n, char *out, size_t cap, size_t *len);
/* An integer 0..4294967295 (no fraction, no exponent) */
bool wire_u32(const char *t, size_t n, uint32_t *out);
/* Any JSON number that fits a double */
bool wire_f64(const char *t, size_t n, double *out);
/*
 * Degrees x 1e7, rounded half away from zero, computed exactly from the
 * decimal text. *in_range: |value| <= limit_e7 exactly. False when the token
 * is not a number or doesn't fit a double.
 */
bool wire_e7(const char *t, size_t n, int64_t limit_e7, int64_t *e7, bool *in_range);

/* An id of 1-64 bytes. Optional: absent or null gives *has = false. */
bool wire_read_id(const char *w, const struct wire_span *sp, bool optional, bool *has,
		  struct proto_id *id);
/* An optional RFC 3339 time: absent or null gives *has = false. */
bool wire_read_time(const char *w, const struct wire_span *sp, bool *has, int64_t *t);

/* ---- Boundary command ---- */

struct boundary_cmd {
	struct proto_id command_id;
	bool has_herd;
	struct proto_id herd_id;
	bool has_collar;
	struct proto_id collar_id;
	uint32_t version;
	bool has_effective_at;
	int64_t effective_at; /* Unix seconds */
	bool track;           /* cue_mode "track"; "audio" is the default */
	bool has_warn;
	double warn_m;
	bool has_hysteresis;
	double hysteresis_m;
	struct shape shape; /* Outer ring then holes, e7, cleaned */
};

/*
 * Scan, verify and read a boundary command. Vertices go into buf (cap
 * vertices; SHAPE_BUF_VERTICES holds any valid command). Herd, collar,
 * version and shape rules are the slot store's (slots_insert).
 */
enum reject_code command_parse(const char *wire, size_t len, const uint8_t public_key[32],
			       struct boundary_cmd *cmd, int32_t (*buf)[2], uint16_t cap);

#endif
```

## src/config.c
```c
#include "config.h"

#include <string.h>

#include "command.h"
#include "store.h"

#define CONFIG_MAGIC 0x3143434fu /* "OCC1" */
#define CONFIG_FORMAT 1

#define F_HAS 0x01
#define F_HERD 0x02
#define F_FAST 0x04
#define F_FAST_UNTIL 0x08
#define F_ENDPOINT 0x10
#define F_TRYING 0x20
#define F_TRIAL_SINCE 0x40

/* magic, format, flags, herd length, pad, version, report_s, poll_s,
 * fast_report_s, fast_poll_s, fast_until, trial_since, herd, endpoint, trial, crc */
#define OFF_VERSION 8
#define OFF_REPORT 12
#define OFF_POLL 16
#define OFF_FAST_REPORT 20
#define OFF_FAST_POLL 24
#define OFF_FAST_UNTIL 28
#define OFF_TRIAL_SINCE 36
#define OFF_HERD 44
#define OFF_ENDPOINT (OFF_HERD + PROTO_MAX_ID_BYTES)
#define OFF_TRIAL (OFF_ENDPOINT + PROTO_MAX_ENDPOINT_BYTES + 1)
#define OFF_CRC (OFF_TRIAL + PROTO_MAX_ENDPOINT_BYTES + 1)
#define CONFIG_BYTES (OFF_CRC + 4)

static uint8_t buf[CONFIG_BYTES];

static void put32(uint8_t *p, uint32_t v)
{
	for (int k = 0; k < 4; k++) {
		p[k] = (uint8_t)(v >> (8 * k));
	}
}

static uint32_t get32(const uint8_t *p)
{
	return (uint32_t)p[0] | (uint32_t)p[1] << 8 | (uint32_t)p[2] << 16 | (uint32_t)p[3] << 24;
}

static void put64(uint8_t *p, int64_t v)
{
	put32(p, (uint32_t)v);
	put32(p + 4, (uint32_t)((uint64_t)v >> 32));
}

static int64_t get64(const uint8_t *p)
{
	return (int64_t)((uint64_t)get32(p) | (uint64_t)get32(p + 4) << 32);
}

/* ---- Parsing and checks ---- */

static bool opt_u32(const char *w, const struct wire_span *sp, bool *has, uint32_t *v)
{
	*has = false;
	if (!sp || wire_is_null(w + sp->val, sp->val_len)) {
		return true;
	}
	*has = wire_u32(w + sp->val, sp->val_len, v);
	return *has;
}

enum reject_code config_parse(const char *wire, size_t len, const uint8_t public_key[32],
			      struct config_cmd *out)
{
	struct wire_scan sc;
	enum reject_code code = wire_verify(wire, len, public_key, &sc);
	const struct wire_span *sp;

	if (code != REJECT_NONE) {
		return code;
	}
	memset(out, 0, sizeof(*out));

	if (!wire_read_id(wire, wire_find(wire, &sc, "command_id"), false, NULL,
			  &out->command_id) ||
	    !wire_read_id(wire, wire_find(wire, &sc, "collar_id"), false, NULL,
			  &out->collar_id) ||
	    !wire_read_id(wire, wire_find(wire, &sc, "herd_id"), true, &out->has_herd,
			  &out->herd_id)) {
		return REJECT_BAD_JSON;
	}

	sp = wire_find(wire, &sc, "version");
	if (!sp || !wire_u32(wire + sp->val, sp->val_len, &out->version)) {
		return REJECT_BAD_JSON;
	}
	sp = wire_find(wire, &sc, "report_s");
	if (!sp || !wire_u32(wire + sp->val, sp->val_len, &out->report_s)) {
		return REJECT_BAD_JSON;
	}
	sp = wire_find(wire, &sc, "poll_s");
	if (!sp || !wire_u32(wire + sp->val, sp->val_len, &out->poll_s)) {
		return REJECT_BAD_JSON;
	}
	if (!opt_u32(wire, wire_find(wire, &sc, "fast_report_s"), &out->has_fast_report,
		     &out->fast_report_s) ||
	    !opt_u32(wire, wire_find(wire, &sc, "fast_poll_s"), &out->has_fast_poll,
		     &out->fast_poll_s) ||
	    !wire_read_time(wire, wire_find(wire, &sc, "fast_until"), &out->has_fast_until,
			    &out->fast_until)) {
		return REJECT_BAD_JSON;
	}

	sp = wire_find(wire, &sc, "endpoint");
	if (sp && !wire_is_null(wire + sp->val, sp->val_len)) {
		if (!wire_string(wire + sp->val, sp->val_len, out->endpoint,
				 PROTO_MAX_ENDPOINT_BYTES, &out->endpoint_len)) {
			return REJECT_BAD_JSON;
		}
		out->has_endpoint = true;
		out->endpoint[out->endpoint_len > PROTO_MAX_ENDPOINT_BYTES ? PROTO_MAX_ENDPOINT_BYTES
									   : out->endpoint_len] =
			'\0';
	}
	return REJECT_NONE;
}

static bool interval_ok(uint32_t s)
{
	return s >= CONFIG_MIN_INTERVAL_S && s <= CONFIG_MAX_INTERVAL_S;
}

enum reject_code config_check(const struct config_cmd *c, const struct proto_id *collar_id,
			      bool has_held, uint32_t held_version)
{
	if (!proto_id_eq(&c->collar_id, collar_id)) {
		return REJECT_WRONG_COLLAR;
	}
	if (has_held && c->version <= held_version) {
		return REJECT_STALE;
	}
	if (!interval_ok(c->report_s) || !interval_ok(c->poll_s) ||
	    (c->has_fast_report && !interval_ok(c->fast_report_s)) ||
	    (c->has_fast_poll && !interval_ok(c->fast_poll_s))) {
		return REJECT_BAD_CONFIG;
	}
	if (c->has_fast_until && !(c->has_fast_report && c->has_fast_poll)) {
		return REJECT_BAD_CONFIG;
	}
	if (c->has_endpoint &&
	    (c->endpoint_len > PROTO_MAX_ENDPOINT_BYTES || c->endpoint_len <= 8 ||
	     memcmp(c->endpoint, "https://", 8) != 0)) {
		return REJECT_BAD_CONFIG;
	}
	return REJECT_NONE;
}

/* ---- State ---- */

void config_init(struct config *c)
{
	memset(c, 0, sizeof(*c));
	c->report_s = CONFIG_DEFAULT_INTERVAL_S;
	c->poll_s = CONFIG_DEFAULT_INTERVAL_S;
}

static void put_str(uint8_t *p, const char *s)
{
	size_t n = strlen(s);

	memset(p, 0, PROTO_MAX_ENDPOINT_BYTES + 1);
	memcpy(p, s, n);
}

static bool get_str(const uint8_t *p, char *out)
{
	if (memchr(p, '\0', PROTO_MAX_ENDPOINT_BYTES + 1) == NULL) {
		return false;
	}
	memcpy(out, p, PROTO_MAX_ENDPOINT_BYTES + 1);
	return true;
}

static void save(struct config *c)
{
	uint8_t flags = 0;

	memset(buf, 0, sizeof(buf));
	flags |= c->has ? F_HAS : 0;
	flags |= c->has_herd ? F_HERD : 0;
	flags |= c->has_fast ? F_FAST : 0;
	flags |= c->has_fast_until ? F_FAST_UNTIL : 0;
	flags |= c->has_endpoint ? F_ENDPOINT : 0;
	flags |= c->trying ? F_TRYING : 0;
	flags |= c->has_trial_since ? F_TRIAL_SINCE : 0;

	put32(buf, CONFIG_MAGIC);
	buf[4] = CONFIG_FORMAT;
	buf[5] = flags;
	buf[6] = c->herd.len;
	put32(buf + OFF_VERSION, c->version);
	put32(buf + OFF_REPORT, c->report_s);
	put32(buf + OFF_POLL, c->poll_s);
	put32(buf + OFF_FAST_REPORT, c->fast_report_s);
	put32(buf + OFF_FAST_POLL, c->fast_poll_s);
	put64(buf + OFF_FAST_UNTIL, c->fast_until);
	put64(buf + OFF_TRIAL_SINCE, c->trial_since);
	memcpy(buf + OFF_HERD, c->herd.s, c->herd.len);
	put_str(buf + OFF_ENDPOINT, c->endpoint);
	put_str(buf + OFF_TRIAL, c->trial);
	put32(buf + OFF_CRC, proto_crc32(0, buf, OFF_CRC));
	if (store_write(STORE_ID_CONFIG, buf, CONFIG_BYTES) != 0) {
		c->store_errors++;
	}
}

void config_load(struct config *c)
{
	int len = store_read(STORE_ID_CONFIG, buf, sizeof(buf));
	struct config t;

	config_init(c);
	if (len != CONFIG_BYTES || get32(buf) != CONFIG_MAGIC || buf[4] != CONFIG_FORMAT ||
	    get32(buf + OFF_CRC) != proto_crc32(0, buf, OFF_CRC)) {
		return;
	}

	uint8_t flags = buf[5];

	config_init(&t);
	t.has = flags & F_HAS;
	t.has_herd = flags & F_HERD;
	t.has_fast = flags & F_FAST;
	t.has_fast_until = flags & F_FAST_UNTIL;
	t.has_endpoint = flags & F_ENDPOINT;
	t.trying = flags & F_TRYING;
	t.has_trial_since = flags & F_TRIAL_SINCE;
	t.version = get32(buf + OFF_VERSION);
	t.report_s = get32(buf + OFF_REPORT);
	t.poll_s = get32(buf + OFF_POLL);
	t.fast_report_s = get32(buf + OFF_FAST_REPORT);
	t.fast_poll_s = get32(buf + OFF_FAST_POLL);
	t.fast_until = get64(buf + OFF_FAST_UNTIL);
	t.trial_since = get64(buf + OFF_TRIAL_SINCE);
	if (t.has_herd && !proto_id_set(&t.herd, (const char *)buf + OFF_HERD, buf[6])) {
		return;
	}
	if (!get_str(buf + OFF_ENDPOINT, t.endpoint) || !get_str(buf + OFF_TRIAL, t.trial) ||
	    !interval_ok(t.report_s) || !interval_ok(t.poll_s)) {
		return;
	}
	*c = t;
}

void config_wipe(struct config *c)
{
	config_init(c);
	if (store_delete(STORE_ID_CONFIG) != 0) {
		c->store_errors++;
	}
}

const char *config_endpoint(const struct config *c, const char *base_endpoint)
{
	if (c->trying) {
		return c->trial;
	}
	return c->has_endpoint ? c->endpoint : base_endpoint;
}

enum reject_code config_receive(struct config *c, const char *wire, size_t len,
				const uint8_t public_key[32], const struct proto_id *collar_id,
				const char *base_endpoint, bool has_now, int64_t now)
{
	struct config_cmd cmd;
	enum reject_code code = config_parse(wire, len, public_key, &cmd);

	if (code == REJECT_NONE) {
		code = config_check(&cmd, collar_id, c->has, c->version);
	}
	if (code != REJECT_NONE) {
		struct wire_scan sc;
		const struct wire_span *sp;
		uint32_t v = 0;

		/* Best effort for the report: the version as sent, if it can be read */
		if (wire_scan(wire, len, &sc) == REJECT_NONE &&
		    (sp = wire_find(wire, &sc, "version")) != NULL) {
			wire_u32(wire + sp->val, sp->val_len, &v);
		}
		c->has_reject = true;
		c->reject_version = v;
		c->reject_code = code;
		return code;
	}

	/* Where reports go now, before this config */
	const char *current = c->has_endpoint ? c->endpoint : base_endpoint;

	c->has = true;
	c->version = cmd.version;
	if (cmd.has_herd) {
		c->has_herd = true;
		c->herd = cmd.herd_id;
	}
	c->report_s = cmd.report_s;
	c->poll_s = cmd.poll_s;
	c->has_fast = cmd.has_fast_report && cmd.has_fast_poll;
	c->fast_report_s = c->has_fast ? cmd.fast_report_s : 0;
	c->fast_poll_s = c->has_fast ? cmd.fast_poll_s : 0;
	c->has_fast_until = cmd.has_fast_until;
	c->fast_until = cmd.has_fast_until ? cmd.fast_until : 0;

	if (cmd.has_endpoint) {
		if (strcmp(cmd.endpoint, current) == 0) {
			c->trying = false; /* Back to the one in use: nothing to try */
			c->has_trial_since = false;
		} else if (!c->trying || strcmp(cmd.endpoint, c->trial) != 0) {
			c->trying = true;
			strcpy(c->trial, cmd.endpoint);
			c->has_trial_since = has_now;
			c->trial_since = has_now ? now : 0;
		}
	}
	save(c);
	return REJECT_NONE;
}

void config_report_result(struct config *c, bool ok, bool has_now, int64_t now)
{
	if (!c->trying) {
		return;
	}
	if (ok) {
		/* The new endpoint works: it becomes the endpoint */
		strcpy(c->endpoint, c->trial);
		c->has_endpoint = true;
		c->trying = false;
		c->has_trial_since = false;
		c->trial[0] = '\0';
		save(c);
		return;
	}
	if (!has_now) {
		return;
	}
	if (!c->has_trial_since) {
		c->has_trial_since = true;
		c->trial_since = now;
		save(c);
	} else if (now - c->trial_since >= CONFIG_ENDPOINT_FALLBACK_S) {
		/* Failed for a day: back to the previous endpoint */
		c->trying = false;
		c->has_trial_since = false;
		c->trial[0] = '\0';
		save(c);
	}
}

void config_cadence(const struct config *c, bool has_now, int64_t now, uint32_t *report_s,
		    uint32_t *poll_s)
{
	if (c->has_fast && c->has_fast_until && has_now && now < c->fast_until) {
		*report_s = c->fast_report_s;
		*poll_s = c->fast_poll_s;
	} else {
		*report_s = c->report_s;
		*poll_s = c->poll_s;
	}
}
```
